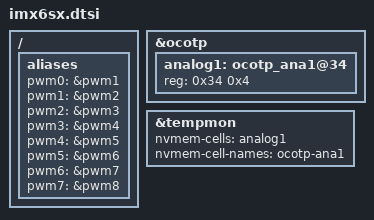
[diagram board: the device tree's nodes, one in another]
/ {
	aliases {
		pwm0 = &pwm1;
		pwm1 = &pwm2;
		pwm2 = &pwm3;
		pwm3 = &pwm4;
		pwm4 = &pwm5;
		pwm5 = &pwm6;
		pwm6 = &pwm7;
		pwm7 = &pwm8;
	};
};

&ocotp {
	#address-cells = <1>;
	#size-cells = <1>;

	analog1: ocotp_ana1@34 {
		reg = <0x34 0x4>;
	};
};

&tempmon {
	nvmem-cells = <&analog1>;
	nvmem-cell-names = "ocotp-ana1";
};
